AUTOSAR XML (schema 00049)
package /Application/DltConfig
  dlt log channel to process mapping DltLogChannelToProcessMapping_SmokingMonitor_TO_SmokingMonitor: dlt-log-channel=SmokingMonitor, process=SmokingMonitor
package /Application/Executable
  executable SmokingMonitor: category=APPLICATION_LEVEL, logging-behavior=USES-LOGGING, reporting-behavior=REPORTS-EXECUTION-STATE, version=1.0.0
    root sw component prototype AA: application-type=SmokingMonitor
package /Application/Manifest
  5 x service instance to port prototype mapping:
    SmokingMonitor_AA_RPort_SOA_DMS: port-prototype=AA.RPort_SOA_DMS, service-instance=EEVP_SmokingMonitor_Consumer_SoaDms
    SmokingMonitor_AA_RPort_SOA_HVAC: port-prototype=AA.RPort_SOA_HVAC, service-instance=EEVP_SmokingMonitor_Consumer_SoaHvac
    SmokingMonitor_AA_RPort_SOA_Mlm: port-prototype=AA.RPort_SOA_Mlm, service-instance=EEVP_SmokingMonitor_Consumer_SoaMlm
    SmokingMonitor_AA_RPort_SOA_SmartFilm: port-prototype=AA.RPort_SOA_SmartFilm, service-instance=EEVP_SmokingMonitor_Consumer_SoaSmartFilm
    SmokingMonitor_AA_RPort_SubscriptionManagement: port-prototype=AA.RPort_SubscriptionManagement, service-instance=EEVP_SmokingMonitor_Consumer_SubscriptionManagement
package /Application/Package/SmokingMonitor/SoftwareCluster_1_0_0
  software cluster SmokingMonitor_SoftwareCluster: category=APPLICATION_LAYER, contained-ar-element=SmokingMonitor, contained-package-element=[SmokingMonitor_AA_RPort_SOA_DMS, SmokingMonitor_AA_RPort_SOA_HVAC, SmokingMonitor_AA_RPort_SOA_Mlm, SmokingMonitor_AA_RPort_SOA_SmartFilm, SmokingMonitor_AA_RPort_SubscriptionManagement], contained-process=SmokingMonitor, vendor-id=403, vendor-signature=ParaCertificate, version=1.0.0
package /Application/Package/SmokingMonitor/SoftwareCluster_1_0_1
  software cluster SmokingMonitor_SoftwareCluster: category=APPLICATION_LAYER, contained-ar-element=SmokingMonitor, contained-package-element=[SmokingMonitor_AA_RPort_SOA_DMS, SmokingMonitor_AA_RPort_SOA_HVAC, SmokingMonitor_AA_RPort_SOA_Mlm, SmokingMonitor_AA_RPort_SOA_SmartFilm, SmokingMonitor_AA_RPort_SubscriptionManagement], contained-process=SmokingMonitor, vendor-id=403, vendor-signature=ParaCertificate, version=1.0.1
package /Application/Package/SmokingMonitor/SoftwareCluster_1_0_2
  software cluster SmokingMonitor_SoftwareCluster: category=APPLICATION_LAYER, contained-ar-element=SmokingMonitor, contained-package-element=[SmokingMonitor_AA_RPort_SOA_DMS, SmokingMonitor_AA_RPort_SOA_HVAC, SmokingMonitor_AA_RPort_SOA_Mlm, SmokingMonitor_AA_RPort_SOA_SmartFilm, SmokingMonitor_AA_RPort_SubscriptionManagement], contained-process=SmokingMonitor, vendor-id=403, vendor-signature=ParaCertificate, version=1.0.2
package /Application/Package/SmokingMonitor/SoftwarePackage
  software package SmokingMonitor_InstallSoftwarePackage_1_0_0: action-type=INSTALL, compressed-software-package-size=0, maximum-supported-ucm-version=1.0.0, minimum-supported-ucm-version=1.0.0, packager-id=403, packager-signature=ParaCertificate, post-verification-reboot=false, pre-activate=SFG05.Off, pre-activation-reboot=false, software-cluster=SoftwareCluster_1_0_0/SmokingMonitor_SoftwareCluster, uncompressed-software-cluster-size=0, verify=SFG05.Verify
  software package SmokingMonitor_RemoveSoftwarePackage_1_0_2: action-type=REMOVE, compressed-software-package-size=0, maximum-supported-ucm-version=1.0.0, minimum-supported-ucm-version=1.0.0, packager-id=403, packager-signature=ParaCertificate, post-verification-reboot=false, pre-activate=SFG05.Off, pre-activation-reboot=false, software-cluster=SoftwareCluster_1_0_2/SmokingMonitor_SoftwareCluster, uncompressed-software-cluster-size=0, verify=SFG05.Verify
  software package SmokingMonitor_UpdateSoftwarePackage_1_0_1: action-type=UPDATE, compressed-software-package-size=0, maximum-supported-ucm-version=1.0.0, minimum-supported-ucm-version=1.0.0, packager-id=403, packager-signature=ParaCertificate, post-verification-reboot=false, pre-activate=SFG05.Off, pre-activation-reboot=false, software-cluster=SoftwareCluster_1_0_1/SmokingMonitor_SoftwareCluster, uncompressed-software-cluster-size=0, verify=SFG05.Verify
package /Application/Package/SmokingMonitor/VehiclePackage
  vehicle package SmokingMonitor_InstallVehiclePackage_1_0_0: vehicle-driver-notification{approval-required=true, notification-state=PROCESS}, packager-signature=ParaCertificate
    rollout-qualifications:
      vehicle rollout step RolloutQualification
        ucm-processings:
          ucm step UcmProcessing: ucm=SmokingMonitor_InstallVehiclePackage_1_0_0/EEVP_UCM
            software package step SoftwarePackageStep: process=SmokingMonitor_InstallSoftwarePackage_1_0_0, transfers=software-package-storing={storing=UCM, transfer=SmokingMonitor_InstallSoftwarePackage_1_0_0}
    ucm description EEVP_UCM: identifier=EEVP_UCM
  vehicle package SmokingMonitor_RemoveVehiclePackage_1_0_2: vehicle-driver-notification{approval-required=true, notification-state=PROCESS}, packager-signature=ParaCertificate
    rollout-qualifications:
      vehicle rollout step RolloutQualification
        ucm-processings:
          ucm step UcmProcessing: ucm=SmokingMonitor_RemoveVehiclePackage_1_0_2/EEVP_UCM
            software package step SoftwarePackageStep: process=SmokingMonitor_RemoveSoftwarePackage_1_0_2, transfers=software-package-storing={storing=UCM, transfer=SmokingMonitor_RemoveSoftwarePackage_1_0_2}
    ucm description EEVP_UCM: identifier=EEVP_UCM
  vehicle package SmokingMonitor_UpdateVehiclePackage_1_0_1: vehicle-driver-notification{approval-required=true, notification-state=PROCESS}, packager-signature=ParaCertificate
    rollout-qualifications:
      vehicle rollout step RolloutQualification
        ucm-processings:
          ucm step UcmProcessing: ucm=SmokingMonitor_UpdateVehiclePackage_1_0_1/EEVP_UCM
            software package step SoftwarePackageStep: process=SmokingMonitor_UpdateSoftwarePackage_1_0_1, transfers=software-package-storing={storing=UCM, transfer=SmokingMonitor_UpdateSoftwarePackage_1_0_1}
    ucm description EEVP_UCM: identifier=EEVP_UCM
package /Application/Process
  process SmokingMonitor: executable=SmokingMonitor, state-dependent-startup-config{function-group-state=[SFG05.On, SFG05.Verify], resource-group=DefaultResourceGroup, startup-config=DefaultStartupConfig}
    process state machine SmokingMonitor: type=ProcessState
package /Application/SwComponent
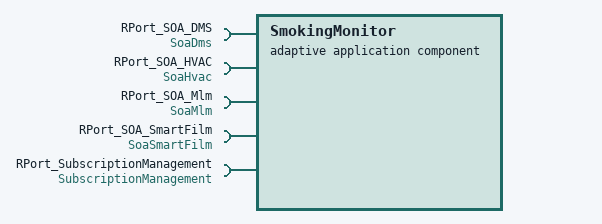
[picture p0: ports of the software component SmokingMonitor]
  adaptive application sw component type SmokingMonitor
    5 x require port:
      RPort_SOA_DMS: required-interface=SoaDms
      RPort_SOA_HVAC: required-interface=SoaHvac
      RPort_SOA_Mlm: required-interface=SoaMlm
      RPort_SOA_SmartFilm: required-interface=SoaSmartFilm
      RPort_SubscriptionManagement: required-interface=SubscriptionManagement
